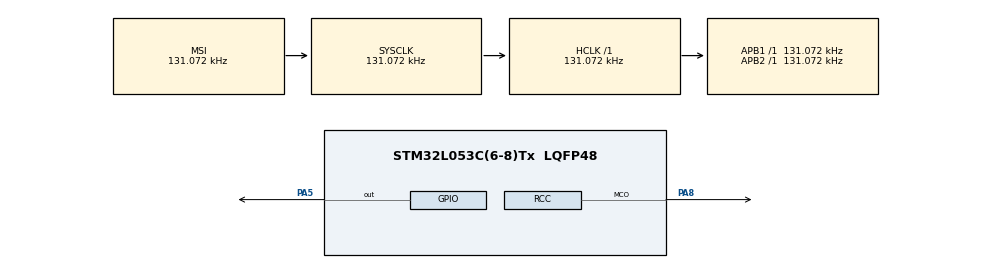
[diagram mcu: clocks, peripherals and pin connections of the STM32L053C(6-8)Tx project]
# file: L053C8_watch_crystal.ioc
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Mcu.Family=STM32L0
Mcu.Name=STM32L053C(6-8)Tx
Mcu.Package=LQFP48
PA5.Signal=GPIO_Output
PA8.Mode=Clock-out
PA8.Signal=RCC_MCO
PC14-OSC32_IN.Mode=LSE-External-Oscillator
PC14-OSC32_IN.Signal=RCC_OSC32_IN
PC15-OSC32_OUT.Mode=LSE-External-Oscillator
PC15-OSC32_OUT.Signal=RCC_OSC32_OUT
ProjectManager.HeapSize=0x200
ProjectManager.StackSize=0x400
ProjectManager.TargetToolchain=SW4STM32
RCC.ADCFreq_Value=4000000
RCC.AHBFreq_Value=131072
RCC.APB1Freq_Value=131072
RCC.APB1TimFreq_Value=131072
RCC.APB2Freq_Value=131072
RCC.APB2TimFreq_Value=131072
RCC.HCLKFreq_Value=131072
RCC.HSE_VALUE=8000000
RCC.HSI16_VALUE=16000000
RCC.HSI48_VALUE=48000000
RCC.HSIRCDiv=4
RCC.HSI_VALUE=4000000
RCC.MSIClockRange=RCC_MSIRANGE_1
RCC.MSI_VALUE=131072
RCC.PLLDIV=RCC_PLLDIV_3
RCC.PWR_Regulator_Voltage_Scale=PWR_REGULATOR_VOLTAGE_SCALE3
RCC.RCC_MCOSource=RCC_MCO1SOURCE_LSE
RCC.RTCClockSelection=RCC_RTCCLKSOURCE_LSE
RCC.RTCClockSelectionVirtual=RCC_RTCCLKSOURCE_LSE
RCC.SYSCLKFreq_VALUE=131072
RCC.VCOOutputFreq_Value=12000000
RCC.VDD_VALUE=3.3
VP_RTC_VS_RTC_Activate.Mode=RTC_Enabled
board=L053C8_watch_crystal

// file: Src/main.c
/**
  ******************************************************************************
  * File Name          : main.c
  * Description        : Main program body
  ******************************************************************************
  *
  * COPYRIGHT(c) 2016 STMicroelectronics
  *
  * Redistribution and use in source and binary forms, with or without modification,
  * are permitted provided that the following conditions are met:
  *   1. Redistributions of source code must retain the above copyright notice,
  *      this list of conditions and the following disclaimer.
  *   2. Redistributions in binary form must reproduce the above copyright notice,
  *      this list of conditions and the following disclaimer in the documentation
  *      and/or other materials provided with the distribution.
  *   3. Neither the name of STMicroelectronics nor the names of its contributors
  *      may be used to endorse or promote products derived from this software
  *      without specific prior written permission.
  *
  * THIS SOFTWARE IS PROVIDED BY THE COPYRIGHT HOLDERS AND CONTRIBUTORS "AS IS"
  * AND ANY EXPRESS OR IMPLIED WARRANTIES, INCLUDING, BUT NOT LIMITED TO, THE
  * IMPLIED WARRANTIES OF MERCHANTABILITY AND FITNESS FOR A PARTICULAR PURPOSE ARE
  * DISCLAIMED. IN NO EVENT SHALL THE COPYRIGHT HOLDER OR CONTRIBUTORS BE LIABLE
  * FOR ANY DIRECT, INDIRECT, INCIDENTAL, SPECIAL, EXEMPLARY, OR CONSEQUENTIAL
  * DAMAGES (INCLUDING, BUT NOT LIMITED TO, PROCUREMENT OF SUBSTITUTE GOODS OR
  * SERVICES; LOSS OF USE, DATA, OR PROFITS; OR BUSINESS INTERRUPTION) HOWEVER
  * CAUSED AND ON ANY THEORY OF LIABILITY, WHETHER IN CONTRACT, STRICT LIABILITY,
  * OR TORT (INCLUDING NEGLIGENCE OR OTHERWISE) ARISING IN ANY WAY OUT OF THE USE
  * OF THIS SOFTWARE, EVEN IF ADVISED OF THE POSSIBILITY OF SUCH DAMAGE.
  *
  ******************************************************************************
  */
#include "main.h"
#include "stm32l0xx_hal.h"
#include "rtc.h"
#include "gpio.h"

/* USER CODE BEGIN PV */
/* Private variables ---------------------------------------------------------*/

/* USER CODE END PV */

void SystemClock_Config(void);
void Error_Handler(void);

/* USER CODE BEGIN PFP */
/* Private function prototypes -----------------------------------------------*/

/* USER CODE END PFP */

int main(void)
{

  /* MCU Configuration----------------------------------------------------------*/

  /* Reset of all peripherals, Initializes the Flash interface and the Systick. */
  HAL_Init();

  /* Configure the system clock */
  SystemClock_Config();

  /* Initialize all configured peripherals */
  MX_GPIO_Init();
  MX_RTC_Init();

  /* USER CODE BEGIN 2 */

  /* Enable Ultra low power mode */
      HAL_PWREx_EnableUltraLowPower();

      HAL_PWR_DisablePVD();

  /* Disable GPIOs clock */
      //
      __HAL_RCC_GPIOB_CLK_DISABLE();
      __HAL_RCC_GPIOC_CLK_DISABLE();
      __HAL_RCC_GPIOH_CLK_DISABLE();

  /* USER CODE END 2 */

  /* Infinite loop */
  while (1)
  {

  /* USER CODE BEGIN 3 */

      //HAL_GPIO_TogglePin(GPIOA, GPIO_PIN_5);
      //HAL_Delay(500);

      HAL_Delay(2000);
      //__HAL_RCC_GPIOA_CLK_DISABLE();
      /* Enter Stop Mode */
      HAL_PWR_EnterSTOPMode(PWR_LOWPOWERREGULATOR_ON, PWR_STOPENTRY_WFE);

  }
  /* USER CODE END 3 */

}

/** System Clock Configuration
*/
void SystemClock_Config(void)
{

  RCC_OscInitTypeDef RCC_OscInitStruct;
  RCC_ClkInitTypeDef RCC_ClkInitStruct;
  RCC_PeriphCLKInitTypeDef PeriphClkInit;

    /**Configure the main internal regulator output voltage
    */
  __HAL_PWR_VOLTAGESCALING_CONFIG(PWR_REGULATOR_VOLTAGE_SCALE3);

    /**Initializes the CPU, AHB and APB busses clocks
    */
  RCC_OscInitStruct.OscillatorType = RCC_OSCILLATORTYPE_LSE|RCC_OSCILLATORTYPE_MSI;
  RCC_OscInitStruct.LSEState = RCC_LSE_ON;
  RCC_OscInitStruct.MSIState = RCC_MSI_ON;
  RCC_OscInitStruct.MSICalibrationValue = 0;
  RCC_OscInitStruct.MSIClockRange = RCC_MSIRANGE_1;
  RCC_OscInitStruct.PLL.PLLState = RCC_PLL_NONE;
  if (HAL_RCC_OscConfig(&RCC_OscInitStruct) != HAL_OK)
  {
    Error_Handler();
  }

    /**Initializes the CPU, AHB and APB busses clocks
    */
  RCC_ClkInitStruct.ClockType = RCC_CLOCKTYPE_HCLK|RCC_CLOCKTYPE_SYSCLK
                              |RCC_CLOCKTYPE_PCLK1|RCC_CLOCKTYPE_PCLK2;
  RCC_ClkInitStruct.SYSCLKSource = RCC_SYSCLKSOURCE_MSI;
  RCC_ClkInitStruct.AHBCLKDivider = RCC_SYSCLK_DIV1;
  RCC_ClkInitStruct.APB1CLKDivider = RCC_HCLK_DIV1;
  RCC_ClkInitStruct.APB2CLKDivider = RCC_HCLK_DIV1;

  if (HAL_RCC_ClockConfig(&RCC_ClkInitStruct, FLASH_LATENCY_0) != HAL_OK)
  {
    Error_Handler();
  }

  PeriphClkInit.PeriphClockSelection = RCC_PERIPHCLK_RTC;
  PeriphClkInit.RTCClockSelection = RCC_RTCCLKSOURCE_LSE;
  if (HAL_RCCEx_PeriphCLKConfig(&PeriphClkInit) != HAL_OK)
  {
    Error_Handler();
  }

  HAL_RCC_MCOConfig(RCC_MCO1, RCC_MCO1SOURCE_LSE, RCC_MCODIV_1);

    /**Configure the Systick interrupt time
    */
  HAL_SYSTICK_Config(HAL_RCC_GetHCLKFreq()/1000);

    /**Configure the Systick
    */
  HAL_SYSTICK_CLKSourceConfig(SYSTICK_CLKSOURCE_HCLK);

  /* SysTick_IRQn interrupt configuration */
  HAL_NVIC_SetPriority(SysTick_IRQn, 0, 0);
}

void Error_Handler(void)
{
  while(1)
  {
  }
}

/************************ (C) COPYRIGHT STMicroelectronics *****END OF FILE****/
